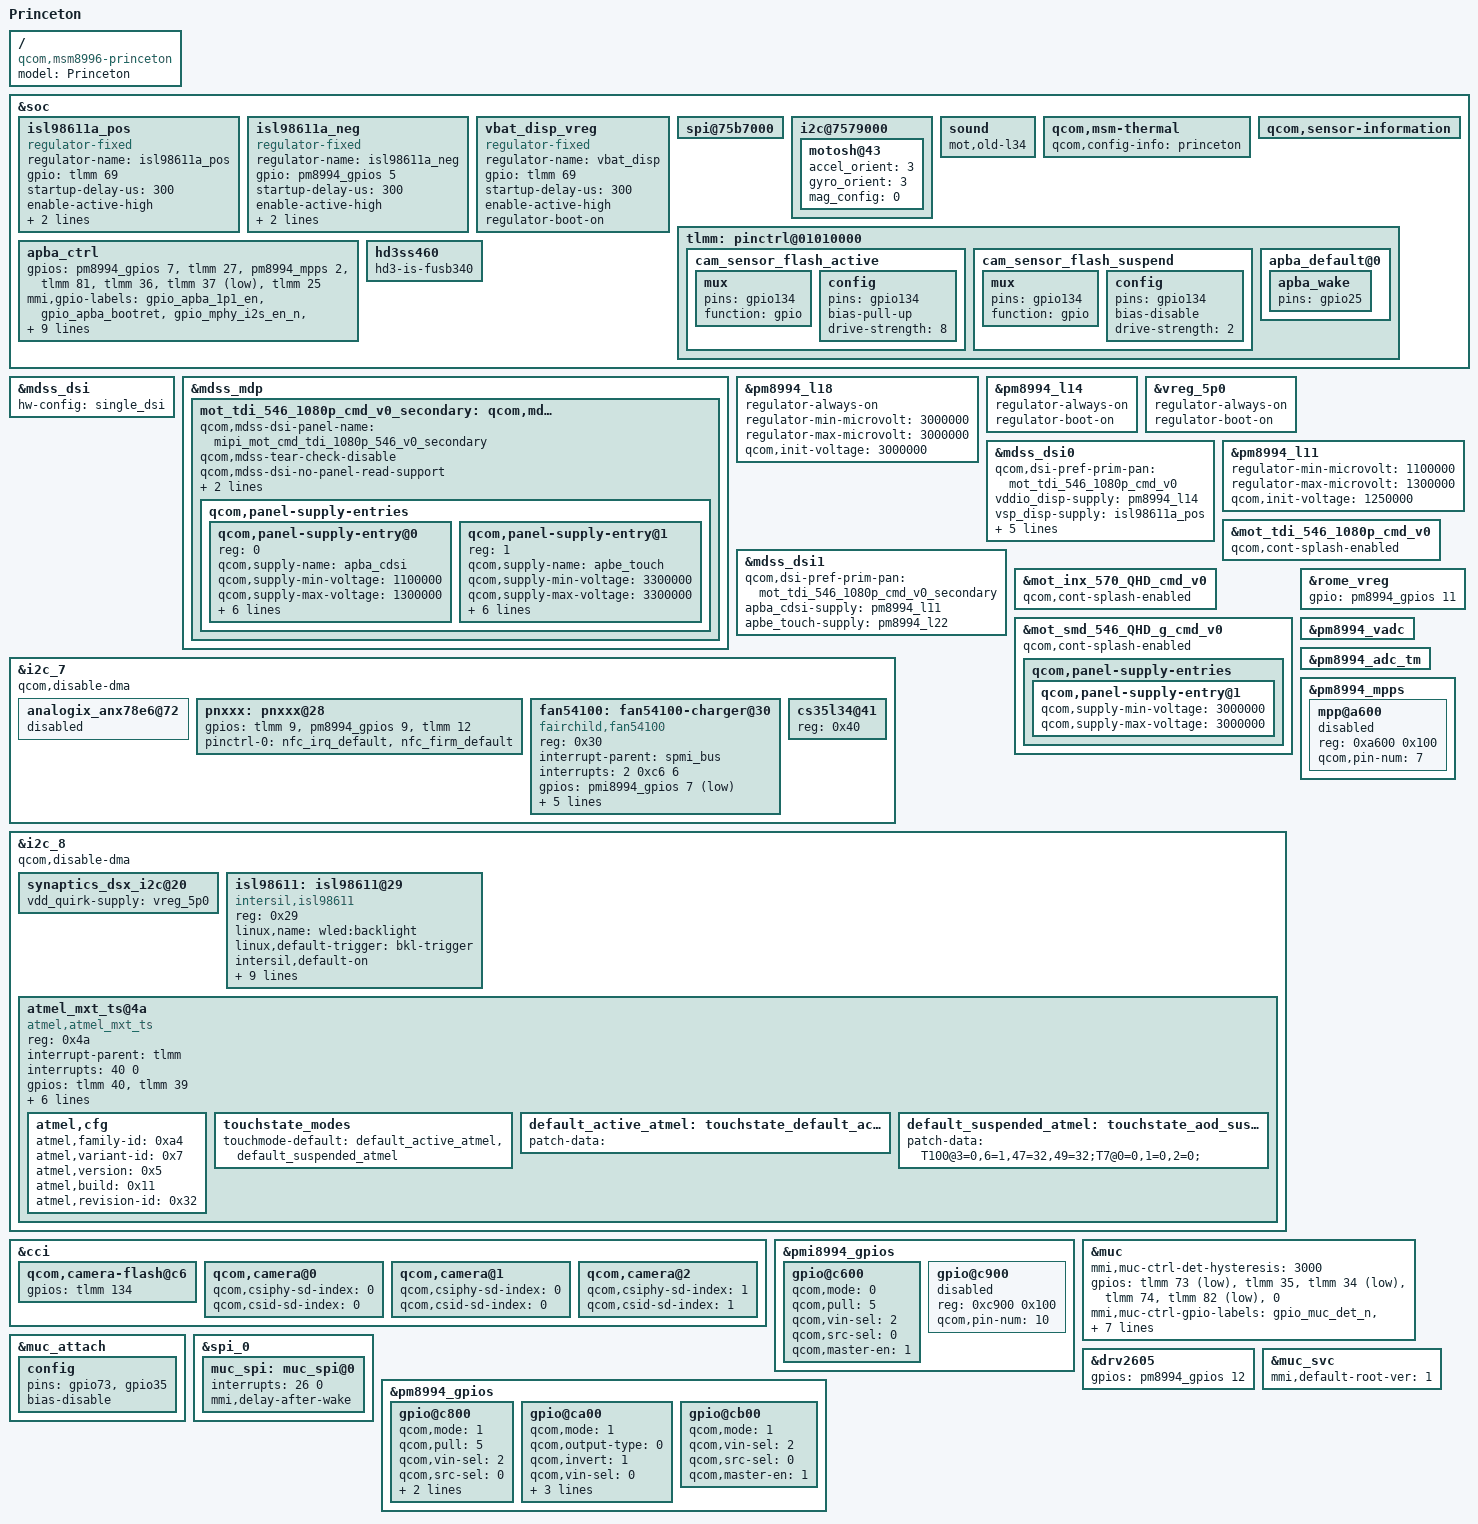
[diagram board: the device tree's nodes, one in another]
/* Copyright (c) 2015, Motorola Mobility Inc. All rights reserved.
 *
 * This program is free software; you can redistribute it and/or modify
 * it under the terms of the GNU General Public License version 2 and
 * only version 2 as published by the Free Software Foundation.
 *
 * This program is distributed in the hope that it will be useful,
 * but WITHOUT ANY WARRANTY; without even the implied warranty of
 * MERCHANTABILITY or FITNESS FOR A PARTICULAR PURPOSE.  See the
 * GNU General Public License for more details.
 */

#include "msm8996-v2.dtsi"
#include "msm8996-moto-common.dtsi"
#include "dsi-panel-mot-tdi-546-1080p-cmd.dtsi"
#include "dsi-panel-mot-inx-570-QHD-cmd.dtsi"
#include "dsi-panel-mot-smd-520-QHD-cmd.dtsi"
#include "dsi-panel-mot-smd-546-QHD-g-cmd.dtsi"

/ {
	model = "Princeton";
	compatible = "qcom,msm8996-princeton", "qcom,msm8996-moto",
			"qcom,msm8996";
};

&soc {
	isl98611a_pos: isl98611a_pos {
		compatible = "regulator-fixed";
		regulator-name = "isl98611a_pos";
		gpio = <&tlmm 69 0>;
		startup-delay-us = <300>;
		enable-active-high;
	};

	isl98611a_neg: isl98611a_neg {
		compatible = "regulator-fixed";
		regulator-name = "isl98611a_neg";
		gpio = <&pm8994_gpios 5 0>;
		startup-delay-us = <300>;
		enable-active-high;
	};

	vbat_disp_vreg: vbat_disp_vreg {
		compatible = "regulator-fixed";
		regulator-name = "vbat_disp";
		gpio = <&tlmm 69 0>;
		startup-delay-us = <300>;
		enable-active-high;
		regulator-boot-on;
	};

	spi@75b7000 {
		/* Need to disable bam because TZ permission issues exist
			on v2 8996 chipset. */
		/delete-property/ qcom,use-bam;
	};

	/* SensorHub Bus */
	i2c@7579000 {
		motosh@43 {
			accel_orient = <3>;   /* Accel Orientation value */
			gyro_orient = <3>;    /* Gyro Orientation value */
			mag_config = <0>;     /* Magnetometer config value */
		};
	};

	sound {
		mot,old-l34;
	};
};

&mdss_dsi {
	hw-config = "single_dsi";
};

&mdss_mdp {
	mot_tdi_546_1080p_cmd_v0_secondary: qcom,mdss_dsi_mot_tdi_546_1080p_cmd_v0_secondary {
		#include "dsi-panel-mot-tdi-546-1080p-cmd-common.dtsi"
	};
};

&mot_tdi_546_1080p_cmd_v0_secondary {
	qcom,mdss-dsi-panel-name = "mipi_mot_cmd_tdi_1080p_546_v0_secondary";
	qcom,mdss-tear-check-disable;
	qcom,mdss-dsi-no-panel-read-support;
	qcom,mdss-dsi-bl-pmic-control-type = "bl_ctrl_mot";
	/delete-property/ qcom,mdss-dsi-on-command;
	/delete-property/ qcom,mdss-dsi-off-command;
	/delete-property/ qcom,mdss-dsi-te-pin-select;
	/delete-property/ qcom,mdss-dsi-te-dcs-command;
	/delete-property/ qcom,mdss-dsi-te-check-enable;
	/delete-property/ qcom,mdss-dsi-te-using-te-pin;
	/delete-node/ qcom,panel-supply-entries;

	qcom,panel-supply-entries {
		#address-cells = <1>;
		#size-cells = <0>;

		qcom,panel-supply-entry@0 {
			reg = <0>;
			qcom,supply-name = "apba_cdsi";
			qcom,supply-min-voltage = <1100000>;
			qcom,supply-max-voltage = <1300000>;
			qcom,supply-enable-load = <300000>;
			qcom,supply-disable-load = <100>;
			qcom,supply-pre-on-sleep = <0>;
			qcom,supply-post-on-sleep = <1>;
			qcom,supply-pre-off-sleep = <0>;
			qcom,supply-post-off-sleep = <1>;
		};

		qcom,panel-supply-entry@1 {
			reg = <1>;
			qcom,supply-name = "apbe_touch";
			qcom,supply-min-voltage = <3300000>;
			qcom,supply-max-voltage = <3300000>;
			qcom,supply-enable-load = <300000>;
			qcom,supply-disable-load = <100>;
			qcom,supply-pre-on-sleep = <0>;
			qcom,supply-post-on-sleep = <2>;
			qcom,supply-pre-off-sleep = <0>;
			qcom,supply-post-off-sleep = <5>;
		};
	};
};

&pm8994_l18 {
	regulator-always-on;
	regulator-min-microvolt = <3000000>;
	regulator-max-microvolt = <3000000>;
	qcom,init-voltage = <3000000>;
};

&isl98611a_pos {
	regulator-always-on;
	regulator-boot-on;
};

&isl98611a_neg {
	regulator-always-on;
	regulator-boot-on;
};

&pm8994_l14 {
	regulator-always-on;
	regulator-boot-on;
};

&vreg_5p0 {
	regulator-always-on;
	regulator-boot-on;
};

&mdss_dsi0 {
	qcom,dsi-pref-prim-pan = <&mot_tdi_546_1080p_cmd_v0>;
	vddio_disp-supply = <&pm8994_l14>;
	vsp_disp-supply = <&isl98611a_pos>;
	vsn_disp-supply = <&isl98611a_neg>;
	vci_disp-supply = <&pm8994_l18>;
	vbat_disp-supply = <&vbat_disp_vreg>;
	vdd3_disp-supply = <&isl98611a_neg>;
	qcom,platform-bklight-en-gpio = <&tlmm 94 0>;
};

&pm8994_l11 {
	regulator-min-microvolt = <1100000>;
	regulator-max-microvolt = <1300000>;
	qcom,init-voltage = <1250000>;
};

&mdss_dsi1 {
	qcom,dsi-pref-prim-pan = <&mot_tdi_546_1080p_cmd_v0_secondary>;
	apba_cdsi-supply = <&pm8994_l11>;
	apbe_touch-supply = <&pm8994_l22>;
};

&mot_tdi_546_1080p_cmd_v0 {
	qcom,cont-splash-enabled;
};

&mot_inx_570_QHD_cmd_v0 {
	qcom,cont-splash-enabled;
};

&mot_smd_546_QHD_g_cmd_v0 {
	qcom,cont-splash-enabled;
	/* Use 3.0v for VCI on Princeton due to other users of that regulator */
	qcom,panel-supply-entries {
		qcom,panel-supply-entry@1 {
			qcom,supply-min-voltage = <3000000>;
			qcom,supply-max-voltage = <3000000>;
		};
	};
};

&i2c_7 {
	analogix_anx78e6@72 {
		status = "disabled";
	};
};


/* 3.3V QCA Supply */
&rome_vreg {
	gpio = <&pm8994_gpios 11 0>;
};

&i2c_7 {
	qcom,disable-dma;
	pnxxx: pnxxx@28 {
		gpios = <&tlmm 9 0>,     /* IRQ */
		    <&pm8994_gpios 9 0>,  /* VEN */
		    <&tlmm 12 0>;  /* Firmware */

		pinctrl-0 = <&nfc_irq_default &nfc_firm_default>;
	};

	fan54100: fan54100-charger@30 {
		compatible = "fairchild,fan54100";
		reg = <0x30>;

		interrupt-parent = <&spmi_bus>;
		interrupts = <2 0xc6 6>;
		gpios = <&pmi8994_gpios 7 0x21>; /* GPIOF_DIR_IN|GPIOF_EXPORT */
		gpio-names = "fan-int-n";
		supply-names = "battery";

		fairchild,sotp-limit-c = <150>;
		fairchild,fovp-limit-mv = <4700>;
		fairchild,ocp-limit-ma = <6200>;
	};
	cs35l34@41 {
		reg = <0x40>;
	};
	/delete-node/ usb3813@2D;
};

&i2c_8 {
	qcom,disable-dma;
	synaptics_dsx_i2c@20 {
		vdd_quirk-supply = <&vreg_5p0>;
	};

	isl98611: isl98611@29 {
		compatible = "intersil,isl98611";
		reg = <0x29>;
		status = "okay";
		linux,name = "wled:backlight";
		linux,default-trigger = "bkl-trigger";
		intersil,default-on;
		intersil,vn = <20>;
		intersil,vp = <20>;
		intersil,panel-tune;
		intersil,pfm-value = <0x86>;
		intersil,dimm-threshold = <0x02>;
		intersil,current-scale = <63>;
		intersil,led-current = <0xC0>;
		intersil,init-level = <255>;
		intersil,no-reset;
	};

	atmel_mxt_ts@4a {
		compatible = "atmel,atmel_mxt_ts";
		reg = <0x4a>;
		interrupt-parent = <&tlmm>;
		interrupts = <40 0>;
		gpios = <&tlmm 40 0>,        /* IRQ */
			<&tlmm 39 0>;        /* RESET */
		touch_vdd-supply = <&pm8994_l22>;
		touch_avdd-supply = <&pm8994_s4>;
		pinctrl-names = "default", "active";
		pinctrl-0 = <&touch_int_default &touch_reset_active>;
		pinctrl-1 = <&touch_int_active &touch_reset_active>;

		atmel,cfg {
			atmel,family-id = <0xa4>;
			atmel,variant-id = <0x7>;
			atmel,version = <0x5>;
			atmel,build = <0x11>;
			atmel,revision-id = <0x32>;
		};

		touchstate_modes {
			touchmode-default = <&default_active_atmel &default_suspended_atmel>;
		};
		default_active_atmel: touchstate_default_active {
			patch-data = "";
		};
		default_suspended_atmel: touchstate_aod_suspended {
			patch-data = "T100@3=0,6=1,47=32,49=32;T7@0=0,1=0,2=0;";
		};
	};

};

&soc {
	qcom,msm-thermal {
		qcom,config-info = "princeton";
	};

	qcom,sensor-information {
		/delete-node/ qcom,sensor-information-38;
	};

	tlmm: pinctrl@01010000 {
		cam_sensor_flash_active: cam_sensor_flash_active {
			/* Flash-En */
			mux {
				pins = "gpio134";
				function = "gpio";
			};

			config {
				pins = "gpio134";
				bias-pull-up; /* PULL Up */
				drive-strength = <8>; /* 2 MA */
			};
		};

		cam_sensor_flash_suspend: cam_sensor_flash_suspend {
				/* RESET, STANDBY */
				mux {
					pins = "gpio134";
					function = "gpio";
				};

				config {
					pins = "gpio134";
					bias-disable; /* No PULL */
					drive-strength = <2>; /* 2 MA */
			};
		};
	};

	apba_ctrl {
		gpios = <&pm8994_gpios 7 2>, /* APBA_1P1_EN, output-high */
			<&tlmm 27 0>,        /* APBA_BOOTRET, output-low */
			<&pm8994_mpps 2 0>,  /* MOD_MPHY_I2S_EN_N, output-low */
			<&tlmm 81 2>,        /* MOD_MPHY_I2S_SEL, output-high */
			<&tlmm 36 0>,       /* APBA_RESET_N, output-low */
			<&tlmm 37 1>,       /* APBA_INT_N, in */
			<&tlmm 25 2>;        /* APBA_WAKE, output-high */
		mmi,gpio-labels = "gpio_apba_1p1_en",
				  "gpio_apba_bootret",
				  "gpio_mphy_i2s_en_n",
				  "gpio_mphy_i2s_sel",
				  "gpio_apba_rst_n",
				  "gpio_apba_int_n",
				  "gpio_apba_wake";
		mmi,int-index = <5>;
		mmi,enable-seq = <6 1 0>, <0 1 0>, <1 0 0>, <2 0 0>, <3 0 0>,
				 <4 0 50>, <4 1 50>;
		mmi,disable-seq = <1 0 0>, <2 0 0>, <3 1 0>, <4 0 50>, <6 0 0>,
				  <0 0 0>;
		mmi,wake-assert-seq = <6 0 0>;
		mmi,wake-deassert-seq = <6 1 0>;
	};

	hd3ss460 {
		hd3-is-fusb340;
	};
};

&cci {
	/* Skyworks 81298 */
	qcom,camera-flash@c6 {
		gpios = <&tlmm 134 0>;
	};

	/* IMX230/IMX338 */
	qcom,camera@0 {
		qcom,csiphy-sd-index = <0>;
		qcom,csid-sd-index = <0>;
	};

	/* IMX214 */
	qcom,camera@1 {
		qcom,csiphy-sd-index = <0>;
		qcom,csid-sd-index = <0>;
	};

	/* OV5693 */
	qcom,camera@2 {
		qcom,csiphy-sd-index = <1>;
		qcom,csid-sd-index = <1>;
	};
};

&muc_spi {
	mmi,delay-after-wake;
};

&pmi8994_gpios {
	gpio@c600 { /* GPIO 7 - FAN54100_INT_N */
		qcom,mode = <0>;		/* Digital Input */
		qcom,pull = <5>;		/* No pull */
		qcom,vin-sel = <2>;
		qcom,src-sel = <0>;		/* GPIO */
		qcom,master-en = <1>;		/* Enable GPIO */
		status = "okay";
	};

	/delete-node/ gpio@c900;
	gpio@c900 {
		reg = <0xc900 0x100>;
		qcom,pin-num = <10>;
		status = "disabled";
	};
};

&pm8994_vadc {
	/delete-node/ chan@26;
};

&pm8994_adc_tm {
	/delete-node/ chan@26;
};

&pm8994_mpps {
	/delete-node/ mpp@a600;
	mpp@a600 {
		reg = <0xa600 0x100>;
		qcom,pin-num = <7>;
		status = "disabled";
	};
};

&muc {
	mmi,muc-ctrl-det-hysteresis = <3000>;

	gpios = <&tlmm 73 1>,   /* gpio_muc_det_n,    input */
		<&tlmm 35 0>,   /* gpio_muc_bplus_en, output-low */
		<&tlmm 34 1>,   /* gpio_muc_int_n,    input */
		<&tlmm 74 2>,   /* gpio_muc_wake_n,   output-high */
		<&tlmm 82 1>,   /* gpio_muc_rdy_n,    input */
		<0>;            /* gpio_muc_ff,       not used */
	mmi,muc-ctrl-gpio-labels = "gpio_muc_det_n",
				"gpio_muc_bplus_en",
				"gpio_muc_int_n",
				"gpio_muc_wake_n",
				"gpio_muc_rdy_n";

	/* v1 CC first, BPLUS second on enable */
	mmi,muc-ctrl-ff-seq-v1 = <0 0 20>, <1 0 100>,
				<0 1 20>, <1 1 100>,
				<0 0 20>;

	/* v2 BPLUS first, v2 CC second on enable */
	mmi,muc-ctrl-ff-seq-v2 = <0 0 100>, <1 0 20>,
				<1 1 100>, <0 1 20>,
				<0 0 20>;

	mmi,muc-det-pin-reconfig;
};

&muc_attach {
	config {
		pins = "gpio73", "gpio35";
		bias-disable;
	};
};

&spi_0 {
	muc_spi: muc_spi@0 {
		interrupts = <26 0>;
	};
};

&tlmm {
	apba_default@0 {
		apba_wake {
			pins = "gpio25";
		};
	};
};

&pm8994_gpios {
	gpio@c800 { /* GPIO 9 - NFC_ENABLE_N */
		status = "okay";
		qcom,mode = <1>; /* Output */
		qcom,pull = <5>; /* None */
		qcom,vin-sel = <2>;
		qcom,src-sel = <0>;
		qcom,out-strength = <1>;
		qcom,master-en = <1>;
	};

	gpio@ca00 { /* GPIO 11 - REG_3P3_ENABLE */
		qcom,mode = <1>;                /* Digital output */
		qcom,output-type = <0>;         /* MOS logic */
		qcom,invert = <1>;              /* Output high */
		qcom,vin-sel = <0>;             /* VPH_PWR */
		qcom,src-sel = <0>;             /* Constant */
		qcom,out-strength = <1>;        /* High drive strength */
		qcom,master-en = <1>;           /* Enable GPIO */
		status = "okay";
	};

	gpio@cb00 { /* GPIO 12 - AP_VIB_EN */
		qcom,mode = <1>;         /* Digital output*/
		qcom,vin-sel = <2>;      /* VIN2 */
		qcom,src-sel = <0>;      /* GPIO */
		qcom,master-en = <1>;    /* Enable GPIO */
		status = "okay";
	};
};

&drv2605 {
	gpios = <&pm8994_gpios 12 0>;   /* EN_GPIO */
};

&muc_svc {
	mmi,default-root-ver = /bits/ 8 <1>;
};
